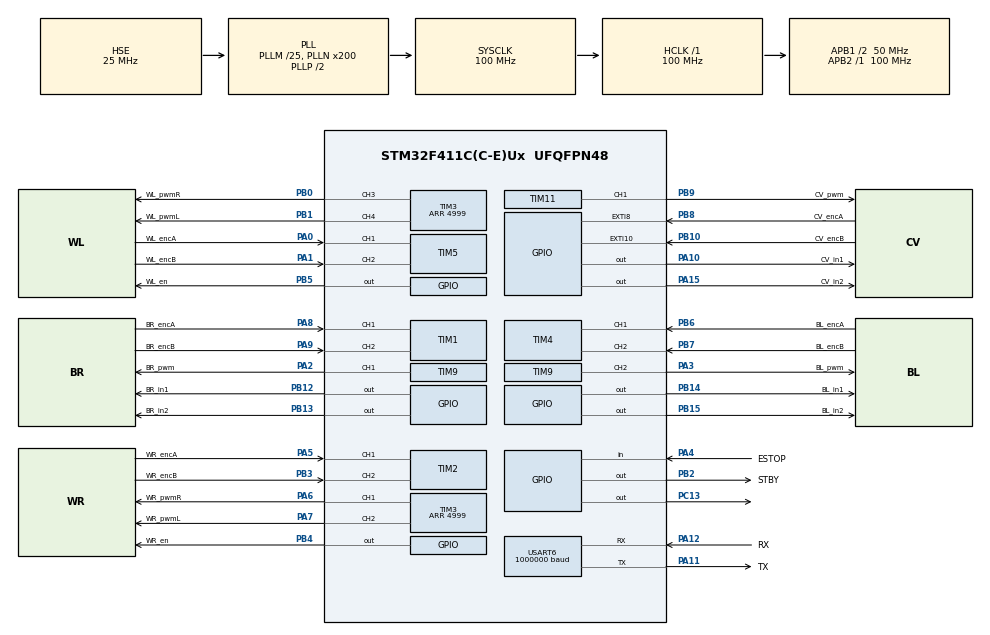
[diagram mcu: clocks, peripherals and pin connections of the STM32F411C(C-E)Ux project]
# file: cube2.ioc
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Dma.Request0=USART6_RX
Dma.Request1=USART6_TX
Dma.USART6_RX.0.Direction=DMA_PERIPH_TO_MEMORY
Dma.USART6_RX.0.FIFOMode=DMA_FIFOMODE_DISABLE
Dma.USART6_RX.0.Instance=DMA2_Stream1
Dma.USART6_RX.0.MemDataAlignment=DMA_MDATAALIGN_BYTE
Dma.USART6_RX.0.MemInc=DMA_MINC_ENABLE
Dma.USART6_RX.0.Mode=DMA_NORMAL
Dma.USART6_RX.0.PeriphDataAlignment=DMA_PDATAALIGN_BYTE
Dma.USART6_RX.0.PeriphInc=DMA_PINC_DISABLE
Dma.USART6_RX.0.Priority=DMA_PRIORITY_HIGH
Dma.USART6_TX.1.Direction=DMA_MEMORY_TO_PERIPH
Dma.USART6_TX.1.FIFOMode=DMA_FIFOMODE_DISABLE
Dma.USART6_TX.1.Instance=DMA2_Stream6
Dma.USART6_TX.1.MemDataAlignment=DMA_MDATAALIGN_BYTE
Dma.USART6_TX.1.MemInc=DMA_MINC_ENABLE
Dma.USART6_TX.1.Mode=DMA_NORMAL
Dma.USART6_TX.1.PeriphDataAlignment=DMA_PDATAALIGN_BYTE
Dma.USART6_TX.1.PeriphInc=DMA_PINC_DISABLE
Dma.USART6_TX.1.Priority=DMA_PRIORITY_MEDIUM
Mcu.Family=STM32F4
Mcu.Name=STM32F411C(C-E)Ux
Mcu.Package=UFQFPN48
NVIC.DMA2_Stream1_IRQn=true\:4\:0\:true\:false\:true\:true\:true\:true
NVIC.DMA2_Stream6_IRQn=true\:3\:0\:true\:false\:true\:true\:true\:true
NVIC.EXTI15_10_IRQn=true\:1\:0\:true\:false\:true\:true\:true\:true
NVIC.EXTI9_5_IRQn=true\:1\:0\:true\:false\:true\:true\:true\:true
NVIC.PriorityGroup=NVIC_PRIORITYGROUP_4
NVIC.TIM1_CC_IRQn=true\:1\:0\:true\:false\:true\:true\:true\:true
NVIC.TIM1_UP_TIM10_IRQn=true\:2\:0\:true\:false\:true\:true\:true\:true
NVIC.TIM2_IRQn=true\:1\:0\:true\:false\:true\:true\:true\:true
NVIC.TIM4_IRQn=true\:1\:0\:true\:false\:true\:true\:true\:true
NVIC.TIM5_IRQn=true\:1\:0\:true\:false\:true\:true\:true\:true
NVIC.USART6_IRQn=true\:3\:0\:true\:false\:true\:true\:true\:true
PA0-WKUP.GPIO_Label=WL_encA
PA0-WKUP.Signal=S_TIM5_CH1
PA1.GPIO_Label=WL_encB
PA1.Signal=S_TIM5_CH2
PA10.GPIO_Label=CV_in1
PA10.Signal=GPIO_Output
PA11.GPIO_Label=TX
PA11.Mode=Asynchronous
PA11.Signal=USART6_TX
PA12.GPIO_Label=RX
PA12.Mode=Asynchronous
PA12.Signal=USART6_RX
PA13.Mode=Serial_Wire
PA13.Signal=SYS_JTMS-SWDIO
PA14.Mode=Serial_Wire
PA14.Signal=SYS_JTCK-SWCLK
PA15.GPIO_Label=CV_in2
PA15.Signal=GPIO_Output
PA2.GPIO_Label=BR_pwm
PA2.Signal=S_TIM9_CH1
PA3.GPIO_Label=BL_pwm
PA3.Signal=S_TIM9_CH2
PA4.GPIO_Label=ESTOP
PA4.GPIO_PuPd=GPIO_PULLUP
PA4.Signal=GPIO_Input
PA5.GPIO_Label=WR_encA
PA5.Signal=S_TIM2_CH1_ETR
PA6.GPIO_Label=WR_pwmR
PA6.Signal=S_TIM3_CH1
PA7.GPIO_Label=WR_pwmL
PA7.Signal=S_TIM3_CH2
PA8.GPIO_Label=BR_encA
PA8.Signal=S_TIM1_CH1
PA9.GPIO_Label=BR_encB
PA9.Signal=S_TIM1_CH2
PB0.GPIO_Label=WL_pwmR
PB0.Signal=S_TIM3_CH3
PB1.GPIO_Label=WL_pwmL
PB1.Signal=S_TIM3_CH4
PB10.GPIO_Label=CV_encB
PB10.GPIO_ModeDefaultEXTI=GPIO_MODE_IT_RISING_FALLING
PB10.Signal=GPXTI10
PB12.GPIO_Label=BR_in1
PB12.Signal=GPIO_Output
PB13.GPIO_Label=BR_in2
PB13.Signal=GPIO_Output
PB14.GPIO_Label=BL_in1
PB14.Signal=GPIO_Output
PB15.GPIO_Label=BL_in2
PB15.Signal=GPIO_Output
PB2.GPIO_Label=STBY
PB2.Signal=GPIO_Output
PB3.GPIO_Label=WR_encB
PB3.Signal=S_TIM2_CH2
PB4.GPIO_Label=WR_en
PB4.Signal=GPIO_Output
PB5.GPIO_Label=WL_en
PB5.Signal=GPIO_Output
PB6.GPIO_Label=BL_encA
PB6.Signal=S_TIM4_CH1
PB7.GPIO_Label=BL_encB
PB7.Signal=S_TIM4_CH2
PB8.GPIO_Label=CV_encA
PB8.GPIO_ModeDefaultEXTI=GPIO_MODE_IT_RISING_FALLING
PB8.Signal=GPXTI8
PB9.GPIO_Label=CV_pwm
PB9.Signal=S_TIM11_CH1
PC13-ANTI_TAMP.Signal=GPIO_Output
PC14-OSC32_IN.Mode=LSE-External-Oscillator
PC14-OSC32_IN.Signal=RCC_OSC32_IN
PC15-OSC32_OUT.Mode=LSE-External-Oscillator
PC15-OSC32_OUT.Signal=RCC_OSC32_OUT
PH0\ -\ OSC_IN.Mode=HSE-External-Oscillator
PH0\ -\ OSC_IN.Signal=RCC_OSC_IN
PH1\ -\ OSC_OUT.Mode=HSE-External-Oscillator
PH1\ -\ OSC_OUT.Signal=RCC_OSC_OUT
ProjectManager.HeapSize=0x200
ProjectManager.StackSize=0x400
ProjectManager.TargetToolchain=STM32CubeIDE
RCC.48MHZClocksFreq_Value=50000000
RCC.AHBFreq_Value=100000000
RCC.APB1CLKDivider=RCC_HCLK_DIV2
RCC.APB1Freq_Value=50000000
RCC.APB1TimFreq_Value=100000000
RCC.APB2Freq_Value=100000000
RCC.APB2TimFreq_Value=100000000
RCC.CortexFreq_Value=100000000
RCC.HCLKFreq_Value=100000000
RCC.HSE_VALUE=25000000
RCC.HSI_VALUE=16000000
RCC.PLLM=25
RCC.PLLN=200
RCC.PLLSourceVirtual=RCC_PLLSOURCE_HSE
RCC.SYSCLKFreq_VALUE=100000000
RCC.SYSCLKSource=RCC_SYSCLKSOURCE_PLLCLK
RCC.VCOOutputFreq_Value=200000000
SH.S_TIM11_CH1.0=TIM11_CH1,PWM Generation1 CH1
SH.S_TIM1_CH1.0=TIM1_CH1,Encoder_Interface
SH.S_TIM1_CH2.0=TIM1_CH2,Encoder_Interface
SH.S_TIM2_CH1_ETR.0=TIM2_CH1,Encoder_Interface
SH.S_TIM2_CH2.0=TIM2_CH2,Encoder_Interface
SH.S_TIM3_CH1.0=TIM3_CH1,PWM Generation1 CH1
SH.S_TIM3_CH2.0=TIM3_CH2,PWM Generation2 CH2
SH.S_TIM3_CH3.0=TIM3_CH3,PWM Generation3 CH3
SH.S_TIM3_CH4.0=TIM3_CH4,PWM Generation4 CH4
SH.S_TIM4_CH1.0=TIM4_CH1,Encoder_Interface
SH.S_TIM4_CH2.0=TIM4_CH2,Encoder_Interface
SH.S_TIM5_CH1.0=TIM5_CH1,Encoder_Interface
SH.S_TIM5_CH2.0=TIM5_CH2,Encoder_Interface
SH.S_TIM9_CH1.0=TIM9_CH1,PWM Generation1 CH1
SH.S_TIM9_CH2.0=TIM9_CH2,PWM Generation2 CH2
TIM1.EncoderMode=TIM_ENCODERMODE_TI12
TIM1.IC1Filter=0
TIM1.IC1Polarity=TIM_ICPOLARITY_RISING
TIM10.Period=9999
TIM10.Prescaler=99
TIM11.AutoReloadPreload=TIM_AUTORELOAD_PRELOAD_ENABLE
TIM11.Channel=TIM_CHANNEL_1
TIM11.Period=4999
TIM2.EncoderMode=TIM_ENCODERMODE_TI12
TIM3.AutoReloadPreload=TIM_AUTORELOAD_PRELOAD_ENABLE
TIM3.Channel-PWM\ Generation1\ CH1=TIM_CHANNEL_1
TIM3.Channel-PWM\ Generation2\ CH2=TIM_CHANNEL_2
TIM3.Channel-PWM\ Generation3\ CH3=TIM_CHANNEL_3
TIM3.Channel-PWM\ Generation4\ CH4=TIM_CHANNEL_4
TIM3.Period=4999
TIM4.EncoderMode=TIM_ENCODERMODE_TI12
TIM5.EncoderMode=TIM_ENCODERMODE_TI12
TIM9.AutoReloadPreload=TIM_AUTORELOAD_PRELOAD_ENABLE
TIM9.Channel-PWM\ Generation1\ CH1=TIM_CHANNEL_1
TIM9.Channel-PWM\ Generation2\ CH2=TIM_CHANNEL_2
TIM9.Period=4999
USART6.BaudRate=1000000
USART6.VirtualMode=VM_ASYNC
VP_TIM10_VS_ClockSourceINT.Mode=Enable_Timer
VP_TIM11_VS_ClockSourceINT.Mode=Enable_Timer
board=custom

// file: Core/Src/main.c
/* USER CODE BEGIN Header */
/**
  ******************************************************************************
  * @file           : main.c
  * @brief          : Main program body
  ******************************************************************************
  * @attention
  *
  * Copyright (c) 2026 STMicroelectronics.
  * All rights reserved.
  *
  * This software is licensed under terms that can be found in the LICENSE file
  * in the root directory of this software component.
  * If no LICENSE file comes with this software, it is provided AS-IS.
  *
  ******************************************************************************
  */
/* USER CODE END Header */
#include "main.h"

/* USER CODE BEGIN Includes */
#include "app.h"
/* USER CODE END Includes */

TIM_HandleTypeDef htim1;
TIM_HandleTypeDef htim2;
TIM_HandleTypeDef htim3;
TIM_HandleTypeDef htim4;
TIM_HandleTypeDef htim5;
TIM_HandleTypeDef htim9;
TIM_HandleTypeDef htim10;
TIM_HandleTypeDef htim11;

UART_HandleTypeDef huart6;
DMA_HandleTypeDef hdma_usart6_rx;
DMA_HandleTypeDef hdma_usart6_tx;

void SystemClock_Config(void);
static void MX_GPIO_Init(void);
static void MX_DMA_Init(void);
static void MX_TIM1_Init(void);
static void MX_TIM2_Init(void);
static void MX_TIM3_Init(void);
static void MX_TIM4_Init(void);
static void MX_TIM5_Init(void);
static void MX_TIM11_Init(void);
static void MX_TIM9_Init(void);
static void MX_TIM10_Init(void);
static void MX_USART6_UART_Init(void);

int main(void)
{

  /* MCU Configuration--------------------------------------------------------*/

  /* Reset of all peripherals, Initializes the Flash interface and the Systick. */
  HAL_Init();

  /* Configure the system clock */
  SystemClock_Config();

  /* Initialize all configured peripherals */
  MX_GPIO_Init();
  MX_DMA_Init();
  MX_TIM1_Init();
  MX_TIM2_Init();
  MX_TIM3_Init();
  MX_TIM4_Init();
  MX_TIM5_Init();
  MX_TIM11_Init();
  MX_TIM9_Init();
  MX_TIM10_Init();
  MX_USART6_UART_Init();
  /* USER CODE BEGIN 2 */
  App_Init();
  /* USER CODE END 2 */

  /* Infinite loop */
  while (1)
  {

    /* USER CODE BEGIN 3 */
    App_Task();
  }
  /* USER CODE END 3 */
}

void SystemClock_Config(void)
{
  RCC_OscInitTypeDef RCC_OscInitStruct = {0};
  RCC_ClkInitTypeDef RCC_ClkInitStruct = {0};

  /** Configure the main internal regulator output voltage
  */
  __HAL_RCC_PWR_CLK_ENABLE();
  __HAL_PWR_VOLTAGESCALING_CONFIG(PWR_REGULATOR_VOLTAGE_SCALE1);

  /** Initializes the RCC Oscillators according to the specified parameters
  * in the RCC_OscInitTypeDef structure.
  */
  RCC_OscInitStruct.OscillatorType = RCC_OSCILLATORTYPE_HSE;
  RCC_OscInitStruct.HSEState = RCC_HSE_ON;
  RCC_OscInitStruct.PLL.PLLState = RCC_PLL_ON;
  RCC_OscInitStruct.PLL.PLLSource = RCC_PLLSOURCE_HSE;
  RCC_OscInitStruct.PLL.PLLM = 25;
  RCC_OscInitStruct.PLL.PLLN = 200;
  RCC_OscInitStruct.PLL.PLLP = RCC_PLLP_DIV2;
  RCC_OscInitStruct.PLL.PLLQ = 4;
  if (HAL_RCC_OscConfig(&RCC_OscInitStruct) != HAL_OK)
  {
    Error_Handler();
  }

  /** Initializes the CPU, AHB and APB buses clocks
  */
  RCC_ClkInitStruct.ClockType = RCC_CLOCKTYPE_HCLK|RCC_CLOCKTYPE_SYSCLK
                              |RCC_CLOCKTYPE_PCLK1|RCC_CLOCKTYPE_PCLK2;
  RCC_ClkInitStruct.SYSCLKSource = RCC_SYSCLKSOURCE_PLLCLK;
  RCC_ClkInitStruct.AHBCLKDivider = RCC_SYSCLK_DIV1;
  RCC_ClkInitStruct.APB1CLKDivider = RCC_HCLK_DIV2;
  RCC_ClkInitStruct.APB2CLKDivider = RCC_HCLK_DIV1;

  if (HAL_RCC_ClockConfig(&RCC_ClkInitStruct, FLASH_LATENCY_3) != HAL_OK)
  {
    Error_Handler();
  }
}

static void MX_TIM1_Init(void)
{

  TIM_Encoder_InitTypeDef sConfig = {0};
  TIM_MasterConfigTypeDef sMasterConfig = {0};

  htim1.Instance = TIM1;
  htim1.Init.Prescaler = 0;
  htim1.Init.CounterMode = TIM_COUNTERMODE_UP;
  htim1.Init.Period = 65535;
  htim1.Init.ClockDivision = TIM_CLOCKDIVISION_DIV1;
  htim1.Init.RepetitionCounter = 0;
  htim1.Init.AutoReloadPreload = TIM_AUTORELOAD_PRELOAD_DISABLE;
  sConfig.EncoderMode = TIM_ENCODERMODE_TI12;
  sConfig.IC1Polarity = TIM_ICPOLARITY_RISING;
  sConfig.IC1Selection = TIM_ICSELECTION_DIRECTTI;
  sConfig.IC1Prescaler = TIM_ICPSC_DIV1;
  sConfig.IC1Filter = 0;
  sConfig.IC2Polarity = TIM_ICPOLARITY_RISING;
  sConfig.IC2Selection = TIM_ICSELECTION_DIRECTTI;
  sConfig.IC2Prescaler = TIM_ICPSC_DIV1;
  sConfig.IC2Filter = 0;
  if (HAL_TIM_Encoder_Init(&htim1, &sConfig) != HAL_OK)
  {
    Error_Handler();
  }
  sMasterConfig.MasterOutputTrigger = TIM_TRGO_RESET;
  sMasterConfig.MasterSlaveMode = TIM_MASTERSLAVEMODE_DISABLE;
  if (HAL_TIMEx_MasterConfigSynchronization(&htim1, &sMasterConfig) != HAL_OK)
  {
    Error_Handler();
  }

}

static void MX_TIM2_Init(void)
{

  TIM_Encoder_InitTypeDef sConfig = {0};
  TIM_MasterConfigTypeDef sMasterConfig = {0};

  htim2.Instance = TIM2;
  htim2.Init.Prescaler = 0;
  htim2.Init.CounterMode = TIM_COUNTERMODE_UP;
  htim2.Init.Period = 4294967295;
  htim2.Init.ClockDivision = TIM_CLOCKDIVISION_DIV1;
  htim2.Init.AutoReloadPreload = TIM_AUTORELOAD_PRELOAD_DISABLE;
  sConfig.EncoderMode = TIM_ENCODERMODE_TI12;
  sConfig.IC1Polarity = TIM_ICPOLARITY_RISING;
  sConfig.IC1Selection = TIM_ICSELECTION_DIRECTTI;
  sConfig.IC1Prescaler = TIM_ICPSC_DIV1;
  sConfig.IC1Filter = 0;
  sConfig.IC2Polarity = TIM_ICPOLARITY_RISING;
  sConfig.IC2Selection = TIM_ICSELECTION_DIRECTTI;
  sConfig.IC2Prescaler = TIM_ICPSC_DIV1;
  sConfig.IC2Filter = 0;
  if (HAL_TIM_Encoder_Init(&htim2, &sConfig) != HAL_OK)
  {
    Error_Handler();
  }
  sMasterConfig.MasterOutputTrigger = TIM_TRGO_RESET;
  sMasterConfig.MasterSlaveMode = TIM_MASTERSLAVEMODE_DISABLE;
  if (HAL_TIMEx_MasterConfigSynchronization(&htim2, &sMasterConfig) != HAL_OK)
  {
    Error_Handler();
  }

}

static void MX_TIM3_Init(void)
{

  TIM_MasterConfigTypeDef sMasterConfig = {0};
  TIM_OC_InitTypeDef sConfigOC = {0};

  htim3.Instance = TIM3;
  htim3.Init.Prescaler = 0;
  htim3.Init.CounterMode = TIM_COUNTERMODE_UP;
  htim3.Init.Period = 4999;
  htim3.Init.ClockDivision = TIM_CLOCKDIVISION_DIV1;
  htim3.Init.AutoReloadPreload = TIM_AUTORELOAD_PRELOAD_ENABLE;
  if (HAL_TIM_PWM_Init(&htim3) != HAL_OK)
  {
    Error_Handler();
  }
  sMasterConfig.MasterOutputTrigger = TIM_TRGO_RESET;
  sMasterConfig.MasterSlaveMode = TIM_MASTERSLAVEMODE_DISABLE;
  if (HAL_TIMEx_MasterConfigSynchronization(&htim3, &sMasterConfig) != HAL_OK)
  {
    Error_Handler();
  }
  sConfigOC.OCMode = TIM_OCMODE_PWM1;
  sConfigOC.Pulse = 0;
  sConfigOC.OCPolarity = TIM_OCPOLARITY_HIGH;
  sConfigOC.OCFastMode = TIM_OCFAST_DISABLE;
  if (HAL_TIM_PWM_ConfigChannel(&htim3, &sConfigOC, TIM_CHANNEL_1) != HAL_OK)
  {
    Error_Handler();
  }
  if (HAL_TIM_PWM_ConfigChannel(&htim3, &sConfigOC, TIM_CHANNEL_2) != HAL_OK)
  {
    Error_Handler();
  }
  if (HAL_TIM_PWM_ConfigChannel(&htim3, &sConfigOC, TIM_CHANNEL_3) != HAL_OK)
  {
    Error_Handler();
  }
  if (HAL_TIM_PWM_ConfigChannel(&htim3, &sConfigOC, TIM_CHANNEL_4) != HAL_OK)
  {
    Error_Handler();
  }
  HAL_TIM_MspPostInit(&htim3);

}

static void MX_TIM4_Init(void)
{

  TIM_Encoder_InitTypeDef sConfig = {0};
  TIM_MasterConfigTypeDef sMasterConfig = {0};

  htim4.Instance = TIM4;
  htim4.Init.Prescaler = 0;
  htim4.Init.CounterMode = TIM_COUNTERMODE_UP;
  htim4.Init.Period = 65535;
  htim4.Init.ClockDivision = TIM_CLOCKDIVISION_DIV1;
  htim4.Init.AutoReloadPreload = TIM_AUTORELOAD_PRELOAD_DISABLE;
  sConfig.EncoderMode = TIM_ENCODERMODE_TI12;
  sConfig.IC1Polarity = TIM_ICPOLARITY_RISING;
  sConfig.IC1Selection = TIM_ICSELECTION_DIRECTTI;
  sConfig.IC1Prescaler = TIM_ICPSC_DIV1;
  sConfig.IC1Filter = 0;
  sConfig.IC2Polarity = TIM_ICPOLARITY_RISING;
  sConfig.IC2Selection = TIM_ICSELECTION_DIRECTTI;
  sConfig.IC2Prescaler = TIM_ICPSC_DIV1;
  sConfig.IC2Filter = 0;
  if (HAL_TIM_Encoder_Init(&htim4, &sConfig) != HAL_OK)
  {
    Error_Handler();
  }
  sMasterConfig.MasterOutputTrigger = TIM_TRGO_RESET;
  sMasterConfig.MasterSlaveMode = TIM_MASTERSLAVEMODE_DISABLE;
  if (HAL_TIMEx_MasterConfigSynchronization(&htim4, &sMasterConfig) != HAL_OK)
  {
    Error_Handler();
  }

}

static void MX_TIM5_Init(void)
{

  TIM_Encoder_InitTypeDef sConfig = {0};
  TIM_MasterConfigTypeDef sMasterConfig = {0};

  htim5.Instance = TIM5;
  htim5.Init.Prescaler = 0;
  htim5.Init.CounterMode = TIM_COUNTERMODE_UP;
  htim5.Init.Period = 4294967295;
  htim5.Init.ClockDivision = TIM_CLOCKDIVISION_DIV1;
  htim5.Init.AutoReloadPreload = TIM_AUTORELOAD_PRELOAD_DISABLE;
  sConfig.EncoderMode = TIM_ENCODERMODE_TI12;
  sConfig.IC1Polarity = TIM_ICPOLARITY_RISING;
  sConfig.IC1Selection = TIM_ICSELECTION_DIRECTTI;
  sConfig.IC1Prescaler = TIM_ICPSC_DIV1;
  sConfig.IC1Filter = 0;
  sConfig.IC2Polarity = TIM_ICPOLARITY_RISING;
  sConfig.IC2Selection = TIM_ICSELECTION_DIRECTTI;
  sConfig.IC2Prescaler = TIM_ICPSC_DIV1;
  sConfig.IC2Filter = 0;
  if (HAL_TIM_Encoder_Init(&htim5, &sConfig) != HAL_OK)
  {
    Error_Handler();
  }
  sMasterConfig.MasterOutputTrigger = TIM_TRGO_RESET;
  sMasterConfig.MasterSlaveMode = TIM_MASTERSLAVEMODE_DISABLE;
  if (HAL_TIMEx_MasterConfigSynchronization(&htim5, &sMasterConfig) != HAL_OK)
  {
    Error_Handler();
  }

}

static void MX_TIM9_Init(void)
{

  TIM_OC_InitTypeDef sConfigOC = {0};

  htim9.Instance = TIM9;
  htim9.Init.Prescaler = 0;
  htim9.Init.CounterMode = TIM_COUNTERMODE_UP;
  htim9.Init.Period = 4999;
  htim9.Init.ClockDivision = TIM_CLOCKDIVISION_DIV1;
  htim9.Init.AutoReloadPreload = TIM_AUTORELOAD_PRELOAD_ENABLE;
  if (HAL_TIM_PWM_Init(&htim9) != HAL_OK)
  {
    Error_Handler();
  }
  sConfigOC.OCMode = TIM_OCMODE_PWM1;
  sConfigOC.Pulse = 0;
  sConfigOC.OCPolarity = TIM_OCPOLARITY_HIGH;
  sConfigOC.OCFastMode = TIM_OCFAST_DISABLE;
  if (HAL_TIM_PWM_ConfigChannel(&htim9, &sConfigOC, TIM_CHANNEL_1) != HAL_OK)
  {
    Error_Handler();
  }
  if (HAL_TIM_PWM_ConfigChannel(&htim9, &sConfigOC, TIM_CHANNEL_2) != HAL_OK)
  {
    Error_Handler();
  }
  HAL_TIM_MspPostInit(&htim9);

}

static void MX_TIM10_Init(void)
{

  htim10.Instance = TIM10;
  htim10.Init.Prescaler = 99;
  htim10.Init.CounterMode = TIM_COUNTERMODE_UP;
  htim10.Init.Period = 9999;
  htim10.Init.ClockDivision = TIM_CLOCKDIVISION_DIV1;
  htim10.Init.AutoReloadPreload = TIM_AUTORELOAD_PRELOAD_DISABLE;
  if (HAL_TIM_Base_Init(&htim10) != HAL_OK)
  {
    Error_Handler();
  }

}

static void MX_TIM11_Init(void)
{

  TIM_OC_InitTypeDef sConfigOC = {0};

  htim11.Instance = TIM11;
  htim11.Init.Prescaler = 0;
  htim11.Init.CounterMode = TIM_COUNTERMODE_UP;
  htim11.Init.Period = 4999;
  htim11.Init.ClockDivision = TIM_CLOCKDIVISION_DIV1;
  htim11.Init.AutoReloadPreload = TIM_AUTORELOAD_PRELOAD_ENABLE;
  if (HAL_TIM_Base_Init(&htim11) != HAL_OK)
  {
    Error_Handler();
  }
  if (HAL_TIM_PWM_Init(&htim11) != HAL_OK)
  {
    Error_Handler();
  }
  sConfigOC.OCMode = TIM_OCMODE_PWM1;
  sConfigOC.Pulse = 0;
  sConfigOC.OCPolarity = TIM_OCPOLARITY_HIGH;
  sConfigOC.OCFastMode = TIM_OCFAST_DISABLE;
  if (HAL_TIM_PWM_ConfigChannel(&htim11, &sConfigOC, TIM_CHANNEL_1) != HAL_OK)
  {
    Error_Handler();
  }
  HAL_TIM_MspPostInit(&htim11);

}

static void MX_USART6_UART_Init(void)
{

  huart6.Instance = USART6;
  huart6.Init.BaudRate = 1000000;
  huart6.Init.WordLength = UART_WORDLENGTH_8B;
  huart6.Init.StopBits = UART_STOPBITS_1;
  huart6.Init.Parity = UART_PARITY_NONE;
  huart6.Init.Mode = UART_MODE_TX_RX;
  huart6.Init.HwFlowCtl = UART_HWCONTROL_NONE;
  huart6.Init.OverSampling = UART_OVERSAMPLING_16;
  if (HAL_UART_Init(&huart6) != HAL_OK)
  {
    Error_Handler();
  }

}

static void MX_DMA_Init(void)
{

  /* DMA controller clock enable */
  __HAL_RCC_DMA2_CLK_ENABLE();

  /* DMA interrupt init */
  /* DMA2_Stream1_IRQn interrupt configuration */
  HAL_NVIC_SetPriority(DMA2_Stream1_IRQn, 4, 0);
  HAL_NVIC_EnableIRQ(DMA2_Stream1_IRQn);
  /* DMA2_Stream6_IRQn interrupt configuration */
  HAL_NVIC_SetPriority(DMA2_Stream6_IRQn, 3, 0);
  HAL_NVIC_EnableIRQ(DMA2_Stream6_IRQn);

}

static void MX_GPIO_Init(void)
{
  GPIO_InitTypeDef GPIO_InitStruct = {0};

  /* GPIO Ports Clock Enable */
  __HAL_RCC_GPIOC_CLK_ENABLE();
  __HAL_RCC_GPIOH_CLK_ENABLE();
  __HAL_RCC_GPIOA_CLK_ENABLE();
  __HAL_RCC_GPIOB_CLK_ENABLE();

  /*Configure GPIO pin Output Level */
  HAL_GPIO_WritePin(GPIOC, GPIO_PIN_13, GPIO_PIN_RESET);

  /*Configure GPIO pin Output Level */
  HAL_GPIO_WritePin(GPIOB, STBY_Pin|BR_in1_Pin|BR_in2_Pin|BL_in1_Pin
                          |BL_in2_Pin|WR_en_Pin|WL_en_Pin, GPIO_PIN_RESET);

  /*Configure GPIO pin Output Level */
  HAL_GPIO_WritePin(GPIOA, CV_in1_Pin|CV_in2_Pin, GPIO_PIN_RESET);

  /*Configure GPIO pin : PC13 */
  GPIO_InitStruct.Pin = GPIO_PIN_13;
  GPIO_InitStruct.Mode = GPIO_MODE_OUTPUT_PP;
  GPIO_InitStruct.Pull = GPIO_NOPULL;
  GPIO_InitStruct.Speed = GPIO_SPEED_FREQ_LOW;
  HAL_GPIO_Init(GPIOC, &GPIO_InitStruct);

  /*Configure GPIO pin : ESTOP_Pin */
  GPIO_InitStruct.Pin = ESTOP_Pin;
  GPIO_InitStruct.Mode = GPIO_MODE_INPUT;
  GPIO_InitStruct.Pull = GPIO_PULLUP;
  HAL_GPIO_Init(ESTOP_GPIO_Port, &GPIO_InitStruct);

  /*Configure GPIO pins : STBY_Pin BR_in1_Pin BR_in2_Pin BL_in1_Pin
                           BL_in2_Pin WR_en_Pin WL_en_Pin */
  GPIO_InitStruct.Pin = STBY_Pin|BR_in1_Pin|BR_in2_Pin|BL_in1_Pin
                          |BL_in2_Pin|WR_en_Pin|WL_en_Pin;
  GPIO_InitStruct.Mode = GPIO_MODE_OUTPUT_PP;
  GPIO_InitStruct.Pull = GPIO_NOPULL;
  GPIO_InitStruct.Speed = GPIO_SPEED_FREQ_LOW;
  HAL_GPIO_Init(GPIOB, &GPIO_InitStruct);

  /*Configure GPIO pins : CV_encB_Pin CV_encA_Pin */
  GPIO_InitStruct.Pin = CV_encB_Pin|CV_encA_Pin;
  GPIO_InitStruct.Mode = GPIO_MODE_IT_RISING_FALLING;
  GPIO_InitStruct.Pull = GPIO_NOPULL;
  HAL_GPIO_Init(GPIOB, &GPIO_InitStruct);

  /*Configure GPIO pins : CV_in1_Pin CV_in2_Pin */
  GPIO_InitStruct.Pin = CV_in1_Pin|CV_in2_Pin;
  GPIO_InitStruct.Mode = GPIO_MODE_OUTPUT_PP;
  GPIO_InitStruct.Pull = GPIO_NOPULL;
  GPIO_InitStruct.Speed = GPIO_SPEED_FREQ_LOW;
  HAL_GPIO_Init(GPIOA, &GPIO_InitStruct);

  /* EXTI interrupt init*/
  HAL_NVIC_SetPriority(EXTI9_5_IRQn, 1, 0);
  HAL_NVIC_EnableIRQ(EXTI9_5_IRQn);

  HAL_NVIC_SetPriority(EXTI15_10_IRQn, 1, 0);
  HAL_NVIC_EnableIRQ(EXTI15_10_IRQn);

}

void Error_Handler(void)
{
  /* USER CODE BEGIN Error_Handler_Debug */
  App_EmergencyShutdown();
  __disable_irq();
  while (1)
  {
  }
  /* USER CODE END Error_Handler_Debug */
}
